VERSION "oracle-1"

NS_ :

BS_:

BU_: ECU1 ECU2

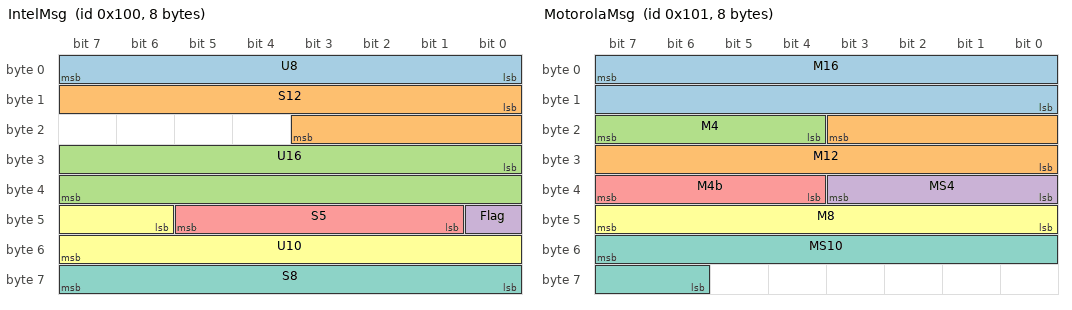
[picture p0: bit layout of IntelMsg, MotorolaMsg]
BO_ 256 IntelMsg: 8 ECU1
 SG_ U8 : 0|8@1+ (1.0,0.0) [0|0] "-" ECU2
 SG_ S12 : 8|12@1- (0.5,-10.0) [0|0] "degC" ECU2
 SG_ U16 : 24|16@1+ (0.01,0.0) [0|0] "V" ECU2
 SG_ Flag : 40|1@1+ (1.0,0.0) [0|0] "" ECU2
 SG_ S5 : 41|5@1- (1.0,0.0) [0|0] "" ECU2
 SG_ U10 : 46|10@1+ (2.0,1.0) [0|0] "" ECU2
 SG_ S8 : 56|8@1- (1.0,0.0) [0|0] "" ECU2

BO_ 257 MotorolaMsg: 8 ECU1
 SG_ M16 : 7|16@0+ (1.0,0.0) [0|0] "" ECU2
 SG_ M12 : 19|12@0+ (1.0,0.0) [0|0] "" ECU2
 SG_ M4 : 23|4@0+ (1.0,0.0) [0|0] "" ECU2
 SG_ MS4 : 35|4@0- (3.0,-1.0) [0|0] "" ECU2
 SG_ M4b : 39|4@0+ (1.0,0.0) [0|0] "" ECU2
 SG_ M8 : 47|8@0+ (1.0,0.0) [0|0] "" ECU2
 SG_ MS10 : 55|10@0- (0.125,0.0) [0|0] "" ECU2

BO_ 258 FloatMsg: 8 ECU1
 SG_ F32le : 0|32@1+ (2.0,0.5) [0|0] "" ECU2
 SG_ F32be : 39|32@0+ (1.0,0.0) [0|0] "" ECU2

BO_ 259 Float64Msg: 8 ECU1
 SG_ F64 : 0|64@1+ (1.0,-1.0) [0|0] "" ECU2

BO_ 260 Wide64Msg: 8 ECU1
 SG_ U64 : 0|64@1+ (1.0,0.0) [0|0] "" ECU2

BO_ 261 WideS64Msg: 8 ECU1
 SG_ S64 : 0|64@1- (1.0,0.0) [0|0] "" ECU2

BO_ 262 MotoWideMsg: 8 ECU1
 SG_ MU64 : 7|64@0+ (1.0,0.0) [0|0] "" ECU2

BO_ 2566844672 ExtJ1939Msg: 8 ECU1
 SG_ EngSpeed : 24|16@1+ (0.125,0.0) [0|0] "rpm" ECU2
 SG_ Torque : 8|8@1+ (1.0,-125.0) [0|0] "%" ECU2

BO_ 2147483904 ExtSameNumber: 8 ECU1
 SG_ ExtU8 : 0|8@1+ (10.0,0.0) [0|0] "" ECU2

BO_ 768 FdMsg: 64 ECU1
 SG_ FdFirst : 0|8@1+ (1.0,0.0) [0|0] "" ECU2
 SG_ FdI16 : 200|16@1+ (0.5,0.0) [0|0] "" ECU2
 SG_ FdS32 : 400|32@1- (0.001,100.0) [0|0] "" ECU2
 SG_ FdMoto : 503|16@0- (1.0,0.0) [0|0] "" ECU2
 SG_ FdLast : 504|8@1+ (1.0,0.0) [0|0] "" ECU2

BO_ 2147484417 FdExtMsg: 24 ECU1
 SG_ FdeU32 : 128|32@1+ (1.0,0.0) [0|0] "" ECU2
 SG_ FdeMoto : 167|24@0+ (0.5,0.0) [0|0] "" ECU2

BO_ 1024 SimpleMux: 8 ECU1
 SG_ Sel M : 0|8@1+ (1.0,0.0) [0|0] "" ECU2
 SG_ A0 m0 : 8|16@1+ (1.0,0.0) [0|0] "" ECU2
 SG_ A1 m1 : 8|16@1+ (0.1,0.0) [0|0] "" ECU2
 SG_ B1 m1 : 24|8@1- (1.0,0.0) [0|0] "" ECU2
 SG_ C : 32|8@1+ (1.0,0.0) [0|0] "" ECU2

BO_ 1025 ExtMux: 8 ECU1
 SG_ SelA M : 0|4@1+ (1.0,0.0) [0|0] "" ECU2
 SG_ SelB m1M : 4|4@1+ (1.0,0.0) [0|0] "" ECU2
 SG_ Y m5 : 8|8@1+ (1.0,0.0) [0|0] "" ECU2
 SG_ Z m0 : 16|8@1+ (1.0,0.0) [0|0] "" ECU2
 SG_ W m2 : 24|8@1+ (1.0,0.0) [0|0] "" ECU2
 SG_ Always : 32|8@1+ (1.0,0.0) [0|0] "" ECU2

BO_ 1026 SignedMux: 8 ECU1
 SG_ SSel M : 0|4@1- (1.0,0.0) [0|0] "" ECU2
 SG_ SNeg m15 : 8|8@1+ (1.0,0.0) [0|0] "" ECU2
 SG_ SPos m7 : 16|8@1+ (1.0,0.0) [0|0] "" ECU2

BO_ 2187121907 Gen00: 12 ECU1
 SG_ G00 : 44|12@1- (3.0,0.0) [0|0] "" ECU2

BO_ 2476350259 Gen01: 8 ECU1
 SG_ G01 : 25|33@0- (0.01,100.0) [0|0] "" ECU2

BO_ 2512154142 Gen02: 8 ECU1
 SG_ G02 : 0|63@1+ (-1.0,0.0) [0|0] "" ECU2

BO_ 2610736509 Gen03: 64 ECU1
 SG_ G03 : 44|16@1+ (2.0,-40.0) [0|0] "" ECU2

BO_ 2370586925 Gen04: 12 ECU1
 SG_ G04 : 59|32@1+ (-1.0,-40.0) [0|0] "" ECU2

BO_ 1285 Gen05: 8 ECU1
 SG_ G05 : 25|8@0+ (3.0,-40.0) [0|0] "" ECU2

BO_ 1286 Gen06: 64 ECU1
 SG_ G06 : 424|13@1- (0.01,0.5) [0|0] "" ECU2

BO_ 1287 Gen07: 8 ECU1
 SG_ G07 : 6|12@0- (-1.0,0.0) [0|0] "" ECU2

BO_ 1288 Gen08: 64 ECU1
 SG_ G08 : 403|63@1- (2.0,100.0) [0|0] "" ECU2

BO_ 1289 Gen09: 64 ECU1
 SG_ G09 : 345|13@1- (3.0,-40.0) [0|0] "" ECU2

BO_ 2484960597 Gen10: 12 ECU1
 SG_ G10 : 0|12@1+ (-1.0,0.5) [0|0] "" ECU2

BO_ 1291 Gen11: 24 ECU1
 SG_ G11 : 78|64@1- (0.01,100.0) [0|0] "" ECU2

BO_ 2585781268 Gen12: 8 ECU1
 SG_ G12 : 40|3@1- (3.0,0.0) [0|0] "" ECU2

BO_ 1293 Gen13: 64 ECU1
 SG_ G13 : 54|12@1+ (0.5,100.0) [0|0] "" ECU2

BO_ 2205095257 Gen14: 64 ECU1
 SG_ G14 : 341|32@1+ (0.125,100.0) [0|0] "" ECU2

BO_ 2594544297 Gen15: 12 ECU1
 SG_ G15 : 35|48@0+ (0.01,100.0) [0|0] "" ECU2

BO_ 1296 Gen16: 8 ECU1
 SG_ G16 : 7|48@1- (1.0,100.0) [0|0] "" ECU2

BO_ 1297 Gen17: 8 ECU1
 SG_ G17 : 52|11@0+ (-1.0,0.0) [0|0] "" ECU2

BO_ 2467409044 Gen18: 8 ECU1
 SG_ G18 : 0|64@1- (0.01,100.0) [0|0] "" ECU2

BO_ 1299 Gen19: 24 ECU1
 SG_ G19 : 165|1@1+ (1.0,100.0) [0|0] "" ECU2

BO_ 1300 Gen20: 8 ECU1
 SG_ G20 : 0|64@1- (2.0,100.0) [0|0] "" ECU2

BO_ 1301 Gen21: 24 ECU1
 SG_ G21 : 92|48@1+ (-1.0,-40.0) [0|0] "" ECU2

BO_ 1302 Gen22: 8 ECU1
 SG_ G22 : 21|24@0+ (1.0,100.0) [0|0] "" ECU2

BO_ 1303 Gen23: 8 ECU1
 SG_ G23 : 8|11@0+ (0.01,0.0) [0|0] "" ECU2

BO_ 2212600297 Gen24: 24 ECU1
 SG_ G24 : 148|1@0- (0.125,0.5) [0|0] "" ECU2

BO_ 2449144854 Gen25: 8 ECU1
 SG_ G25 : 14|33@1+ (2.0,-40.0) [0|0] "" ECU2

BO_ 2523955048 Gen26: 8 ECU1
 SG_ G26 : 55|8@0+ (1.0,-40.0) [0|0] "" ECU2

BO_ 1307 Gen27: 8 ECU1
 SG_ G27 : 22|17@1+ (2.0,0.0) [0|0] "" ECU2

BO_ 1308 Gen28: 12 ECU1
 SG_ G28 : 36|32@0+ (1.0,0.0) [0|0] "" ECU2

BO_ 1309 Gen29: 8 ECU1
 SG_ G29 : 2|9@0- (0.01,-40.0) [0|0] "" ECU2

BO_ 1310 Gen30: 8 ECU1
 SG_ G30 : 12|9@0+ (3.0,100.0) [0|0] "" ECU2

BO_ 1311 Gen31: 12 ECU1
 SG_ G31 : 76|12@1+ (0.125,-40.0) [0|0] "" ECU2

BO_ 1312 Gen32: 64 ECU1
 SG_ G32 : 275|5@1- (2.0,0.5) [0|0] "" ECU2

BO_ 1313 Gen33: 12 ECU1
 SG_ G33 : 52|17@1- (0.01,100.0) [0|0] "" ECU2

BO_ 2454868671 Gen34: 8 ECU1
 SG_ G34 : 15|31@0+ (2.0,100.0) [0|0] "" ECU2

BO_ 1315 Gen35: 24 ECU1
 SG_ G35 : 13|48@1- (0.01,0.0) [0|0] "" ECU2

BO_ 1316 Gen36: 8 ECU1
 SG_ G36 : 28|32@1- (0.01,-40.0) [0|0] "" ECU2

BO_ 1317 Gen37: 8 ECU1
 SG_ G37 : 0|64@1+ (0.125,100.0) [0|0] "" ECU2

BO_ 1318 Gen38: 12 ECU1
 SG_ G38 : 2|32@0+ (3.0,0.5) [0|0] "" ECU2

BO_ 2280574069 Gen39: 12 ECU1
 SG_ G39 : 42|2@1+ (-1.0,0.5) [0|0] "" ECU2

BO_ 2659824786 Gen40: 8 ECU1
 SG_ G40 : 53|9@1+ (1.0,0.0) [0|0] "" ECU2

BO_ 1321 Gen41: 8 ECU1
 SG_ G41 : 25|16@0- (1.0,0.0) [0|0] "" ECU2

BO_ 1322 Gen42: 64 ECU1
 SG_ G42 : 208|64@0- (2.0,0.0) [0|0] "" ECU2

BO_ 1323 Gen43: 24 ECU1
 SG_ G43 : 19|12@0+ (-1.0,100.0) [0|0] "" ECU2

BO_ 2673325525 Gen44: 8 ECU1
 SG_ G44 : 33|11@0- (1.0,0.5) [0|0] "" ECU2

BO_ 2567403951 Gen45: 64 ECU1
 SG_ G45 : 275|3@0- (0.5,0.5) [0|0] "" ECU2

BO_ 2548859819 Gen46: 8 ECU1
 SG_ G46 : 34|12@1- (0.125,100.0) [0|0] "" ECU2

BO_ 1327 Gen47: 8 ECU1
 SG_ G47 : 44|11@0- (0.5,0.5) [0|0] "" ECU2

BO_ 2617732249 Gen48: 12 ECU1
 SG_ G48 : 15|5@1+ (0.125,0.5) [0|0] "" ECU2

BO_ 1329 Gen49: 64 ECU1
 SG_ G49 : 423|24@0+ (2.0,0.0) [0|0] "" ECU2

BO_ 1330 Gen50: 12 ECU1
 SG_ G50 : 5|17@0+ (0.5,100.0) [0|0] "" ECU2

BO_ 1331 Gen51: 8 ECU1
 SG_ G51 : 6|9@1+ (2.0,0.0) [0|0] "" ECU2

BO_ 1332 Gen52: 24 ECU1
 SG_ G52 : 187|1@0+ (0.125,0.0) [0|0] "" ECU2

BO_ 1333 Gen53: 12 ECU1
 SG_ G53 : 5|13@0+ (1.0,0.5) [0|0] "" ECU2

BO_ 2225955158 Gen54: 24 ECU1
 SG_ G54 : 4|9@0+ (3.0,0.0) [0|0] "" ECU2

BO_ 1335 Gen55: 8 ECU1
 SG_ G55 : 20|24@0+ (0.5,0.5) [0|0] "" ECU2

BO_ 1336 Gen56: 8 ECU1
 SG_ G56 : 16|3@0+ (1.0,-40.0) [0|0] "" ECU2

BO_ 2379771421 Gen57: 8 ECU1
 SG_ G57 : 38|17@1- (-1.0,100.0) [0|0] "" ECU2

BO_ 2483612192 Gen58: 64 ECU1
 SG_ G58 : 172|31@0- (2.0,0.5) [0|0] "" ECU2

BO_ 2347603237 Gen59: 8 ECU1
 SG_ G59 : 16|24@1- (0.5,0.5) [0|0] "" ECU2

SIG_VALTYPE_ 258 F32le : 1;
SIG_VALTYPE_ 258 F32be : 1;
SIG_VALTYPE_ 259 F64 : 2;
SG_MUL_VAL_ 1025 SelB SelA 1-1;
SG_MUL_VAL_ 1025 Y SelB 5-5, 7-8;
SG_MUL_VAL_ 1025 Z SelA 0-0;
SG_MUL_VAL_ 1025 W SelA 2-3;
VAL_ 256 Flag 0 "Off" 1 "On" ;
VAL_ 256 S5 -1 "Minus one" -16 "Min" 0 "Zero" ;
